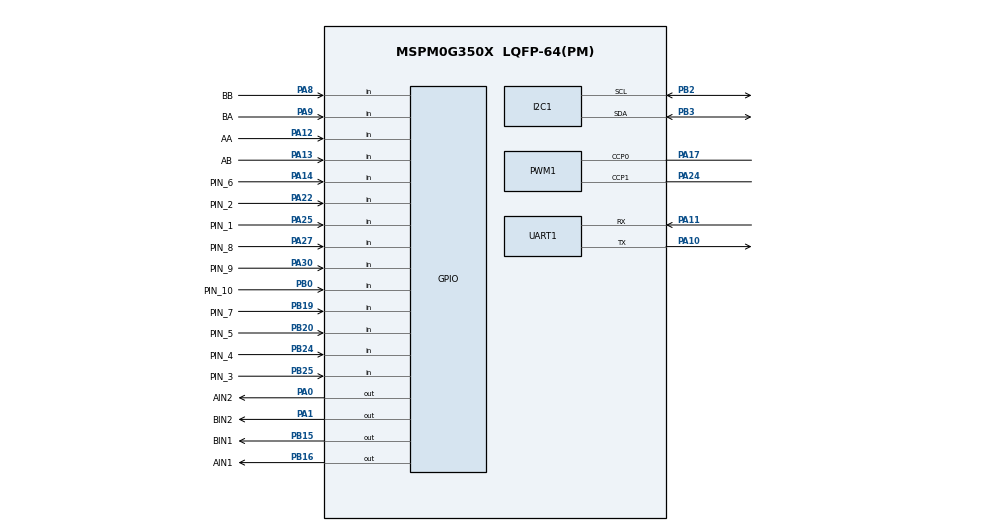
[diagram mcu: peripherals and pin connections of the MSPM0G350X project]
/**
 * @cliArgs --device "MSPM0G350X" --part "Default" --package "LQFP-64(PM)" --product "mspm0_sdk@2.10.00.04"
 * @versions {"tool":"1.26.2+4477"}
 */

/**
 * Import the modules used in this configuration.
 */
const GPIO   = scripting.addModule("/ti/driverlib/GPIO", {}, false);
const GPIO1  = GPIO.addInstance();
const GPIO2  = GPIO.addInstance();
const GPIO3  = GPIO.addInstance();
const GPIO4  = GPIO.addInstance();
const GPIO5  = GPIO.addInstance();
const GPIO6  = GPIO.addInstance();
const I2C    = scripting.addModule("/ti/driverlib/I2C", {}, false);
const I2C1   = I2C.addInstance();
const PWM    = scripting.addModule("/ti/driverlib/PWM", {}, false);
const PWM1   = PWM.addInstance();
const SYSCTL = scripting.addModule("/ti/driverlib/SYSCTL");
const TIMER  = scripting.addModule("/ti/driverlib/TIMER", {}, false);
const TIMER1 = TIMER.addInstance();
const TIMER2 = TIMER.addInstance();
const TIMER3 = TIMER.addInstance();
const UART   = scripting.addModule("/ti/driverlib/UART", {}, false);
const UART1  = UART.addInstance();

/**
 * Write custom configuration values to the imported modules.
 */
GPIO1.$name                         = "LED";
GPIO1.port                          = "PORTB";
GPIO1.associatedPins[0].$name       = "PIN_22";
GPIO1.associatedPins[0].assignedPin = "22";

const Board = scripting.addModule("/ti/driverlib/Board", {}, false);

GPIO2.$name                          = "AIN";
GPIO2.associatedPins.create(2);
GPIO2.associatedPins[0].$name        = "AIN1";
GPIO2.associatedPins[0].pin.$assign  = "PB16";
GPIO2.associatedPins[1].$name        = "AIN2";
GPIO2.associatedPins[1].initialValue = "SET";
GPIO2.associatedPins[1].pin.$assign  = "PA0";

GPIO3.$name                          = "BIN";
GPIO3.associatedPins.create(2);
GPIO3.associatedPins[0].$name        = "BIN1";
GPIO3.associatedPins[0].pin.$assign  = "PB15";
GPIO3.associatedPins[1].$name        = "BIN2";
GPIO3.associatedPins[1].initialValue = "SET";
GPIO3.associatedPins[1].pin.$assign  = "PA1";

GPIO4.$name                               = "A_Encode";
GPIO4.associatedPins.create(2);
GPIO4.associatedPins[0].$name             = "AA";
GPIO4.associatedPins[0].direction         = "INPUT";
GPIO4.associatedPins[0].interruptEn       = true;
GPIO4.associatedPins[0].interruptPriority = "0";
GPIO4.associatedPins[0].polarity          = "RISE";
GPIO4.associatedPins[0].internalResistor  = "PULL_UP";
GPIO4.associatedPins[0].pin.$assign       = "PA12";
GPIO4.associatedPins[1].$name             = "AB";
GPIO4.associatedPins[1].direction         = "INPUT";
GPIO4.associatedPins[1].internalResistor  = "PULL_UP";
GPIO4.associatedPins[1].pin.$assign       = "PA13";

GPIO5.$name                               = "B_Encode";
GPIO5.associatedPins.create(2);
GPIO5.associatedPins[0].$name             = "BA";
GPIO5.associatedPins[0].direction         = "INPUT";
GPIO5.associatedPins[0].interruptEn       = true;
GPIO5.associatedPins[0].interruptPriority = "0";
GPIO5.associatedPins[0].polarity          = "RISE";
GPIO5.associatedPins[0].internalResistor  = "PULL_UP";
GPIO5.associatedPins[0].pin.$assign       = "PA9";
GPIO5.associatedPins[1].$name             = "BB";
GPIO5.associatedPins[1].direction         = "INPUT";
GPIO5.associatedPins[1].internalResistor  = "PULL_UP";
GPIO5.associatedPins[1].pin.$assign       = "PA8";

GPIO6.$name                         = "Grays";
GPIO6.associatedPins.create(10);
GPIO6.associatedPins[0].$name       = "PIN_1";
GPIO6.associatedPins[0].direction   = "INPUT";
GPIO6.associatedPins[0].pin.$assign = "PA25";
GPIO6.associatedPins[1].$name       = "PIN_2";
GPIO6.associatedPins[1].direction   = "INPUT";
GPIO6.associatedPins[1].pin.$assign = "PA22";
GPIO6.associatedPins[2].$name       = "PIN_3";
GPIO6.associatedPins[2].direction   = "INPUT";
GPIO6.associatedPins[2].pin.$assign = "PB25";
GPIO6.associatedPins[3].$name       = "PIN_4";
GPIO6.associatedPins[3].direction   = "INPUT";
GPIO6.associatedPins[3].pin.$assign = "PB24";
GPIO6.associatedPins[4].$name       = "PIN_5";
GPIO6.associatedPins[4].direction   = "INPUT";
GPIO6.associatedPins[4].pin.$assign = "PB20";
GPIO6.associatedPins[5].$name       = "PIN_6";
GPIO6.associatedPins[5].direction   = "INPUT";
GPIO6.associatedPins[5].pin.$assign = "PA14";
GPIO6.associatedPins[6].$name       = "PIN_7";
GPIO6.associatedPins[6].direction   = "INPUT";
GPIO6.associatedPins[6].pin.$assign = "PB19";
GPIO6.associatedPins[7].$name       = "PIN_8";
GPIO6.associatedPins[7].direction   = "INPUT";
GPIO6.associatedPins[7].pin.$assign = "PA27";
GPIO6.associatedPins[8].$name       = "PIN_9";
GPIO6.associatedPins[8].direction   = "INPUT";
GPIO6.associatedPins[8].pin.$assign = "PA30";
GPIO6.associatedPins[9].$name       = "PIN_10";
GPIO6.associatedPins[9].direction   = "INPUT";
GPIO6.associatedPins[9].pin.$assign = "PB0";

I2C1.$name                             = "I2C_1";
I2C1.basicEnableController             = true;
I2C1.peripheral.$assign                = "I2C1";
I2C1.peripheral.sdaPin.$assign         = "PB3";
I2C1.peripheral.sclPin.$assign         = "PB2";
I2C1.sdaPinConfig.$name                = "ti_driverlib_gpio_GPIOPinGeneric4";
I2C1.sdaPinConfig.hideOutputInversion  = scripting.forceWrite(false);
I2C1.sdaPinConfig.onlyInternalResistor = scripting.forceWrite(false);
I2C1.sdaPinConfig.passedPeripheralType = scripting.forceWrite("Digital");
I2C1.sclPinConfig.$name                = "ti_driverlib_gpio_GPIOPinGeneric5";
I2C1.sclPinConfig.hideOutputInversion  = scripting.forceWrite(false);
I2C1.sclPinConfig.onlyInternalResistor = scripting.forceWrite(false);
I2C1.sclPinConfig.passedPeripheralType = scripting.forceWrite("Digital");

PWM1.$name                      = "PWM_0";
PWM1.clockPrescale              = 25;
PWM1.timerCount                 = 128;
PWM1.peripheral.$assign         = "TIMG7";
PWM1.peripheral.ccp0Pin.$assign = "PA17";
PWM1.peripheral.ccp1Pin.$assign = "PA24";
PWM1.PWM_CHANNEL_0.$name        = "ti_driverlib_pwm_PWMTimerCC0";
PWM1.PWM_CHANNEL_0.dutyCycle    = 100;
PWM1.PWM_CHANNEL_1.$name        = "ti_driverlib_pwm_PWMTimerCC1";
PWM1.PWM_CHANNEL_1.dutyCycle    = 100;
PWM1.ccp0PinConfig.$name        = "ti_driverlib_gpio_GPIOPinGeneric0";
PWM1.ccp1PinConfig.$name        = "ti_driverlib_gpio_GPIOPinGeneric1";

SYSCTL.forceDefaultClkConfig = true;
SYSCTL.clockTreeEn           = true;

TIMER1.$name              = "TIMER_TICK";
TIMER1.timerClkDiv        = 8;
TIMER1.timerClkPrescale   = 10;
TIMER1.timerMode          = "PERIODIC";
TIMER1.timerPeriod        = "20 ms";
TIMER1.interruptPriority  = "3";
TIMER1.timerStartTimer    = true;
TIMER1.interrupts         = ["ZERO"];
TIMER1.peripheral.$assign = "TIMA0";

TIMER2.$name              = "LINE_TIMER";
TIMER2.timerClkDiv        = 8;
TIMER2.timerClkPrescale   = 10;
TIMER2.timerMode          = "PERIODIC";
TIMER2.timerPeriod        = "10 ms";
TIMER2.interruptPriority  = "2";
TIMER2.timerStartTimer    = true;
TIMER2.interrupts         = ["ZERO"];
TIMER2.peripheral.$assign = "TIMG6";

TIMER3.$name              = "TIMER_0";
TIMER3.timerClkDiv        = 8;
TIMER3.timerClkPrescale   = 100;
TIMER3.timerMode          = "PERIODIC";
TIMER3.timerPeriod        = "20 ms";
TIMER3.timerStartTimer    = true;
TIMER3.interrupts         = ["ZERO"];
TIMER3.peripheral.$assign = "TIMG0";

UART1.$name                    = "UART_0";
UART1.targetBaudRate           = 115200;
UART1.peripheral.$assign       = "UART0";
UART1.peripheral.rxPin.$assign = "PA11";
UART1.peripheral.txPin.$assign = "PA10";
UART1.txPinConfig.$name        = "ti_driverlib_gpio_GPIOPinGeneric2";
UART1.rxPinConfig.$name        = "ti_driverlib_gpio_GPIOPinGeneric3";

/**
 * Pinmux solution for unlocked pins/peripherals. This ensures that minor changes to the automatic solver in a future
 * version of the tool will not impact the pinmux you originally saw.  These lines can be completely deleted in order to
 * re-solve from scratch.
 */
GPIO1.associatedPins[0].pin.$suggestSolution = "PB22";
Board.peripheral.$suggestSolution            = "DEBUGSS";
Board.peripheral.swclkPin.$suggestSolution   = "PA20";
Board.peripheral.swdioPin.$suggestSolution   = "PA19";
